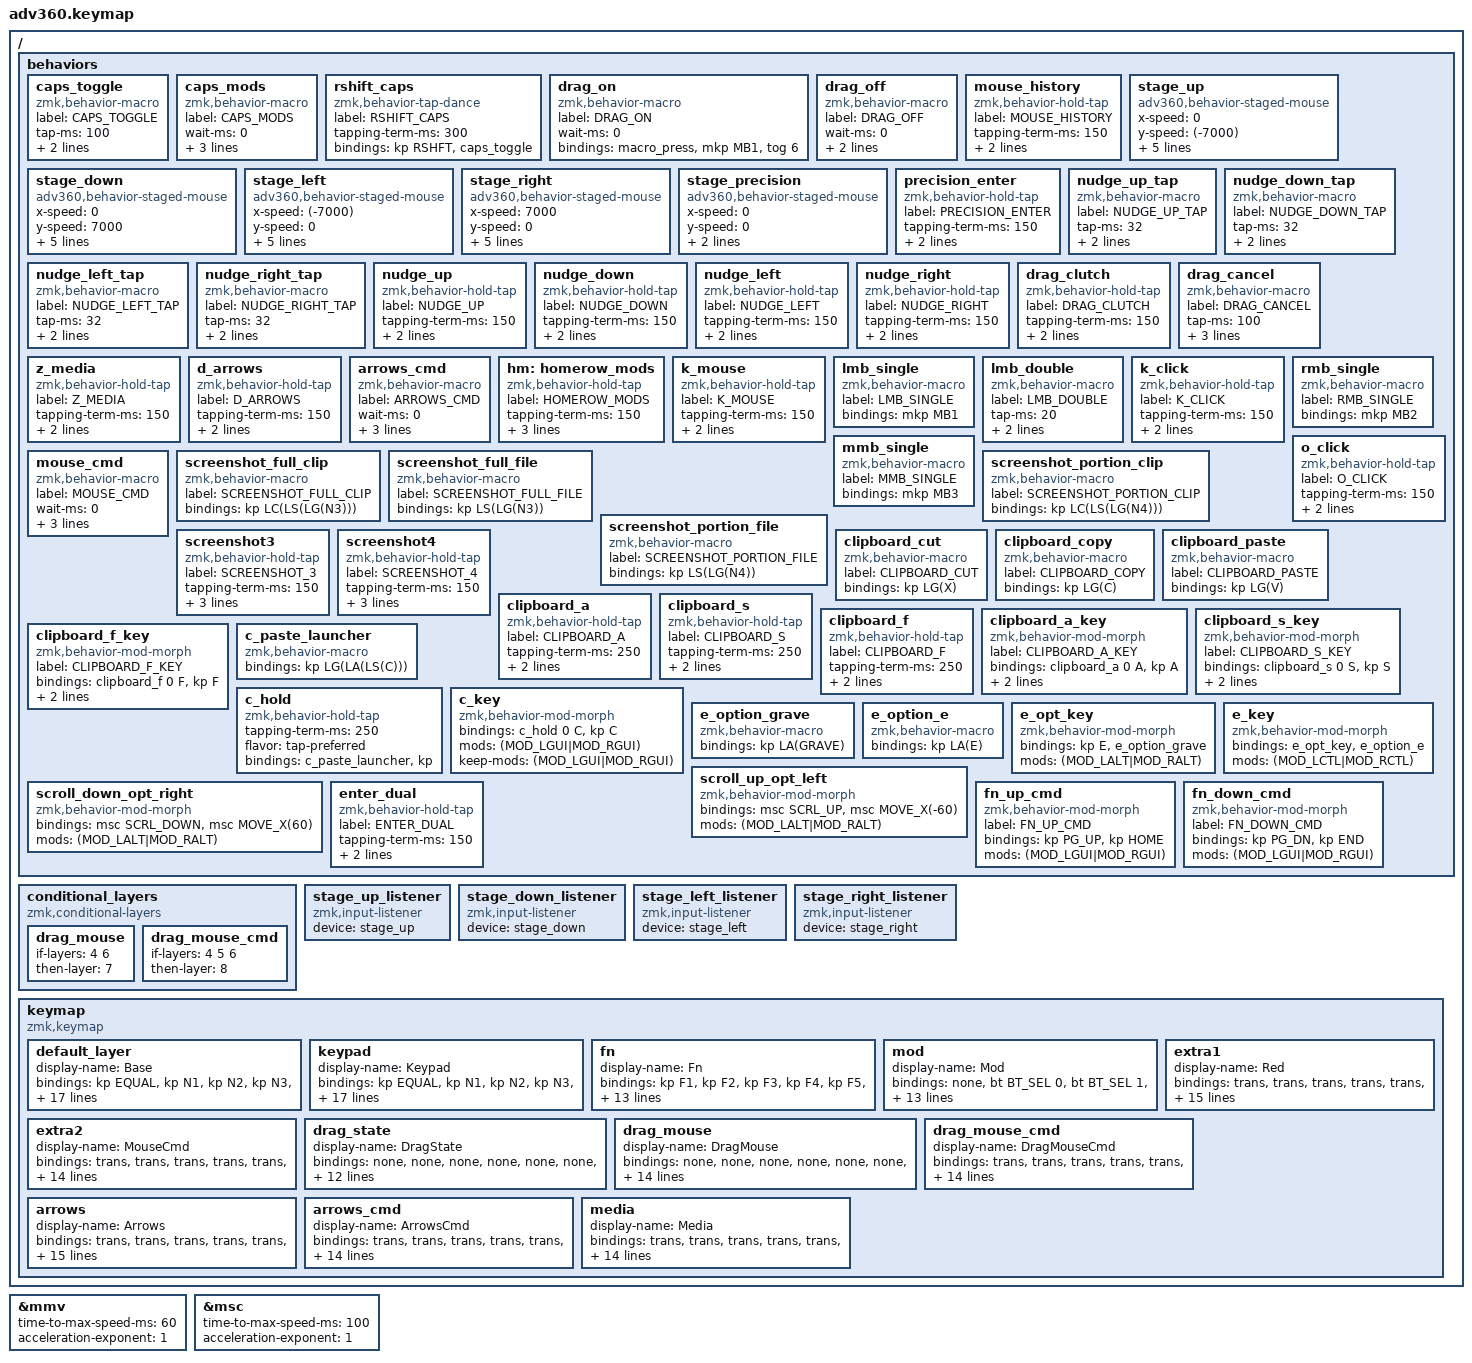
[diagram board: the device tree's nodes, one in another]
/* Rebuild marker: re-trigger the GitHub Actions firmware build; no functional keymap changes. */
#include <behaviors.dtsi>
#include <dt-bindings/zmk/keys.h>
#include <dt-bindings/zmk/modifiers.h>
#include <dt-bindings/zmk/bt.h>
#include <dt-bindings/zmk/rgb.h>
#include <dt-bindings/zmk/stp.h>
#include <dt-bindings/zmk/backlight.h>
#define ZMK_POINTING_DEFAULT_MOVE_VAL 1800
#define ZMK_POINTING_DEFAULT_SCRL_VAL 30
#include <dt-bindings/zmk/pointing.h>

&mmv {
    time-to-max-speed-ms = <60>;
    acceleration-exponent = <1>;
};

&msc {
    time-to-max-speed-ms = <100>;
    acceleration-exponent = <1>;
};

/ {
    behaviors {
      #include "macros.dtsi"
      #include "version.dtsi"

      // Shift double-tap Caps Lock and mouse-layer controls.
      caps_toggle: caps_toggle {
          compatible = "zmk,behavior-macro";
          label = "CAPS_TOGGLE";
          #binding-cells = <0>;
          tap-ms = <100>;
          wait-ms = <0>;
          bindings = <&kp CAPS>;
      };

      // Hold Command, Option, and Shift while the physical Caps key is held.
      caps_mods: caps_mods {
          compatible = "zmk,behavior-macro";
          label = "CAPS_MODS";
          #binding-cells = <0>;
          wait-ms = <0>;
          bindings = <&macro_press &kp LGUI &kp LALT &kp LSHIFT &macro_pause_for_release &macro_release &kp LSHIFT &kp LALT &kp LGUI>;
      };

      rshift_caps: rshift_caps {
          compatible = "zmk,behavior-tap-dance";
          label = "RSHIFT_CAPS";
          #binding-cells = <0>;
          tapping-term-ms = <300>;
          bindings = <&kp RSHFT>, <&caps_toggle>;
      };

      drag_on: drag_on {
          compatible = "zmk,behavior-macro";
          label = "DRAG_ON";
          #binding-cells = <0>;
          wait-ms = <0>;
          bindings = <&macro_press &mkp MB1 &tog 6>;
      };

      drag_off: drag_off {
          compatible = "zmk,behavior-macro";
          label = "DRAG_OFF";
          #binding-cells = <0>;
          wait-ms = <0>;
          bindings = <&macro_release &mkp MB1 &macro_press &tog 6>;
      };

      mouse_history: mouse_history {
          compatible = "zmk,behavior-hold-tap";
          label = "MOUSE_HISTORY";
          #binding-cells = <2>;
          tapping-term-ms = <150>;
          flavor = "tap-preferred";
          bindings = <&kp>, <&kp>;
      };



      // Experimental Rev4: 1 px immediate nudge, continuous smooth ramp from 50 to 7000 px/s over 470 ms; braking disabled.
      stage_up: stage_up {
          compatible = "adv360,behavior-staged-mouse";
          #binding-cells = <0>;
          x-speed = <0>;
          y-speed = <(-7000)>;
          nudge-px = <1>;
          crawl-speed = <50>;
          crawl-ms = <250>;
          ramp-ms = <220>;
          brake-ms = <0>;
      };
      stage_down: stage_down {
          compatible = "adv360,behavior-staged-mouse";
          #binding-cells = <0>;
          x-speed = <0>;
          y-speed = <7000>;
          nudge-px = <1>;
          crawl-speed = <50>;
          crawl-ms = <250>;
          ramp-ms = <220>;
          brake-ms = <0>;
      };
      stage_left: stage_left {
          compatible = "adv360,behavior-staged-mouse";
          #binding-cells = <0>;
          x-speed = <(-7000)>;
          y-speed = <0>;
          nudge-px = <1>;
          crawl-speed = <50>;
          crawl-ms = <250>;
          ramp-ms = <220>;
          brake-ms = <0>;
      };
      stage_right: stage_right {
          compatible = "adv360,behavior-staged-mouse";
          #binding-cells = <0>;
          x-speed = <7000>;
          y-speed = <0>;
          nudge-px = <1>;
          crawl-speed = <50>;
          crawl-ms = <250>;
          ramp-ms = <220>;
          brake-ms = <0>;
      };
      // Enter held while K activates the mouse layer: fixed-speed precision.
      stage_precision: stage_precision {
          compatible = "adv360,behavior-staged-mouse";
          #binding-cells = <0>;
          x-speed = <0>;
          y-speed = <0>;
          nudge-px = <0>;
          brake-ms = <0>;
      };

      precision_enter: precision_enter {
          compatible = "zmk,behavior-hold-tap";
          label = "PRECISION_ENTER";
          #binding-cells = <2>;
          tapping-term-ms = <150>;
          flavor = "balanced";
          bindings = <&stage_precision>, <&kp>;
      };

      // Mouse-layer taps send a fixed short pulse; holds keep continuous movement.
      nudge_up_tap: nudge_up_tap {
          compatible = "zmk,behavior-macro";
          label = "NUDGE_UP_TAP";
          #binding-cells = <0>;
          tap-ms = <32>;
          wait-ms = <0>;
          bindings = <&macro_tap &mmv MOVE(0,-3000)>;
      };

      nudge_down_tap: nudge_down_tap {
          compatible = "zmk,behavior-macro";
          label = "NUDGE_DOWN_TAP";
          #binding-cells = <0>;
          tap-ms = <32>;
          wait-ms = <0>;
          bindings = <&macro_tap &mmv MOVE(0,3000)>;
      };

      nudge_left_tap: nudge_left_tap {
          compatible = "zmk,behavior-macro";
          label = "NUDGE_LEFT_TAP";
          #binding-cells = <0>;
          tap-ms = <32>;
          wait-ms = <0>;
          bindings = <&macro_tap &mmv MOVE(-3000,0)>;
      };

      nudge_right_tap: nudge_right_tap {
          compatible = "zmk,behavior-macro";
          label = "NUDGE_RIGHT_TAP";
          #binding-cells = <0>;
          tap-ms = <32>;
          wait-ms = <0>;
          bindings = <&macro_tap &mmv MOVE(3000,0)>;
      };

      nudge_up: nudge_up {
          compatible = "zmk,behavior-hold-tap";
          label = "NUDGE_UP";
          #binding-cells = <2>;
          tapping-term-ms = <150>;
          flavor = "tap-preferred";
          bindings = <&mmv>, <&nudge_up_tap>;
      };

      nudge_down: nudge_down {
          compatible = "zmk,behavior-hold-tap";
          label = "NUDGE_DOWN";
          #binding-cells = <2>;
          tapping-term-ms = <150>;
          flavor = "tap-preferred";
          bindings = <&mmv>, <&nudge_down_tap>;
      };

      nudge_left: nudge_left {
          compatible = "zmk,behavior-hold-tap";
          label = "NUDGE_LEFT";
          #binding-cells = <2>;
          tapping-term-ms = <150>;
          flavor = "tap-preferred";
          bindings = <&mmv>, <&nudge_left_tap>;
      };

      nudge_right: nudge_right {
          compatible = "zmk,behavior-hold-tap";
          label = "NUDGE_RIGHT";
          #binding-cells = <2>;
          tapping-term-ms = <150>;
          flavor = "tap-preferred";
          bindings = <&mmv>, <&nudge_right_tap>;
      };

      // K can re-enter the mouse layer during drag lock without typing a K.
      drag_clutch: drag_clutch {
          compatible = "zmk,behavior-hold-tap";
          label = "DRAG_CLUTCH";
          #binding-cells = <2>;
          tapping-term-ms = <150>;
          flavor = "balanced";
          bindings = <&mo>, <&none>;
      };


      // Send Escape while MB1 is still held so a drag is cancelled, not dropped.
      drag_cancel: drag_cancel {
          compatible = "zmk,behavior-macro";
          label = "DRAG_CANCEL";
          #binding-cells = <0>;
          tap-ms = <100>;
          wait-ms = <30>;
          bindings = <&macro_tap &kp ESC &macro_release &mkp MB1 &macro_press &tog 6>;
      };


      z_media: z_media {
          compatible = "zmk,behavior-hold-tap";
          label = "Z_MEDIA";
          #binding-cells = <2>;
          tapping-term-ms = <150>;
          flavor = "balanced";
          bindings = <&mo>, <&kp>;
      };

      d_arrows: d_arrows {
          compatible = "zmk,behavior-hold-tap";
          label = "D_ARROWS";
          #binding-cells = <2>;
          tapping-term-ms = <150>;
          flavor = "balanced";
          bindings = <&mo>, <&kp>;
      };

      arrows_cmd: arrows_cmd {
          compatible = "zmk,behavior-macro";
          label = "ARROWS_CMD";
          #binding-cells = <0>;
          wait-ms = <0>;
          bindings = <&macro_press &kp LGUI &mo 10 &macro_pause_for_release &macro_release &mo 10 &kp LGUI>;
      };

      hm: homerow_mods {
          compatible = "zmk,behavior-hold-tap";
          label = "HOMEROW_MODS";
          #binding-cells = <2>;
          tapping-term-ms = <150>;
          quick_tap_ms = <175>;
          flavor = "tap-preferred";
          bindings = <&kp>, <&kp>;
      };

      k_mouse: k_mouse {
          compatible = "zmk,behavior-hold-tap";
          label = "K_MOUSE";
          #binding-cells = <2>;
          tapping-term-ms = <150>;
          flavor = "balanced";
          bindings = <&mo>, <&kp>;
      };

      lmb_single: lmb_single {
          compatible = "zmk,behavior-macro";
          label = "LMB_SINGLE";
          #binding-cells = <0>;
          bindings = <&mkp MB1>;
      };

      lmb_double: lmb_double {
          compatible = "zmk,behavior-macro";
          label = "LMB_DOUBLE";
          #binding-cells = <0>;
          tap-ms = <20>;
          wait-ms = <40>;
          bindings = <&mkp MB1 &mkp MB1>;
      };

      k_click: k_click {
          compatible = "zmk,behavior-hold-tap";
          label = "K_CLICK";
          #binding-cells = <2>;
          tapping-term-ms = <150>;
          flavor = "tap-preferred";
          bindings = <&lmb_double>, <&lmb_single>;
      };

      rmb_single: rmb_single {
          compatible = "zmk,behavior-macro";
          label = "RMB_SINGLE";
          #binding-cells = <0>;
          bindings = <&mkp MB2>;
      };

      mmb_single: mmb_single {
          compatible = "zmk,behavior-macro";
          label = "MMB_SINGLE";
          #binding-cells = <0>;
          bindings = <&mkp MB3>;
      };

      o_click: o_click {
          compatible = "zmk,behavior-hold-tap";
          label = "O_CLICK";
          #binding-cells = <2>;
          tapping-term-ms = <150>;
          flavor = "tap-preferred";
          bindings = <&mmb_single>, <&rmb_single>;
      };

      mouse_cmd: mouse_cmd {
          compatible = "zmk,behavior-macro";
          label = "MOUSE_CMD";
          #binding-cells = <0>;
          wait-ms = <0>;
          bindings = <&macro_press &kp LGUI &mo 5 &macro_pause_for_release &macro_release &mo 5 &kp LGUI>;
      };

      screenshot_full_clip: screenshot_full_clip {
          compatible = "zmk,behavior-macro";
          label = "SCREENSHOT_FULL_CLIP";
          #binding-cells = <0>;
          bindings = <&kp LC(LS(LG(N3)))>;
      };

      screenshot_full_file: screenshot_full_file {
          compatible = "zmk,behavior-macro";
          label = "SCREENSHOT_FULL_FILE";
          #binding-cells = <0>;
          bindings = <&kp LS(LG(N3))>;
      };

      screenshot_portion_clip: screenshot_portion_clip {
          compatible = "zmk,behavior-macro";
          label = "SCREENSHOT_PORTION_CLIP";
          #binding-cells = <0>;
          bindings = <&kp LC(LS(LG(N4)))>;
      };

      screenshot_portion_file: screenshot_portion_file {
          compatible = "zmk,behavior-macro";
          label = "SCREENSHOT_PORTION_FILE";
          #binding-cells = <0>;
          bindings = <&kp LS(LG(N4))>;
      };

      screenshot3: screenshot3 {
          compatible = "zmk,behavior-hold-tap";
          label = "SCREENSHOT_3";
          #binding-cells = <2>;
          tapping-term-ms = <150>;
          flavor = "tap-preferred";
          bindings = <&screenshot_full_file>, <&screenshot_full_clip>;
      };

      screenshot4: screenshot4 {
          compatible = "zmk,behavior-hold-tap";
          label = "SCREENSHOT_4";
          #binding-cells = <2>;
          tapping-term-ms = <150>;
          flavor = "tap-preferred";
          bindings = <&screenshot_portion_file>, <&screenshot_portion_clip>;
      };

      clipboard_cut: clipboard_cut {
          compatible = "zmk,behavior-macro";
          label = "CLIPBOARD_CUT";
          #binding-cells = <0>;
          bindings = <&kp LG(X)>;
      };

      clipboard_copy: clipboard_copy {
          compatible = "zmk,behavior-macro";
          label = "CLIPBOARD_COPY";
          #binding-cells = <0>;
          bindings = <&kp LG(C)>;
      };

      clipboard_paste: clipboard_paste {
          compatible = "zmk,behavior-macro";
          label = "CLIPBOARD_PASTE";
          #binding-cells = <0>;
          bindings = <&kp LG(V)>;
      };

      clipboard_a: clipboard_a {
          compatible = "zmk,behavior-hold-tap";
          label = "CLIPBOARD_A";
          #binding-cells = <2>;
          tapping-term-ms = <250>;
          flavor = "tap-preferred";
          bindings = <&clipboard_cut>, <&kp>;
      };

      clipboard_s: clipboard_s {
          compatible = "zmk,behavior-hold-tap";
          label = "CLIPBOARD_S";
          #binding-cells = <2>;
          tapping-term-ms = <250>;
          flavor = "tap-preferred";
          bindings = <&clipboard_copy>, <&kp>;
      };

      clipboard_f: clipboard_f {
          compatible = "zmk,behavior-hold-tap";
          label = "CLIPBOARD_F";
          #binding-cells = <2>;
          tapping-term-ms = <250>;
          flavor = "tap-preferred";
          bindings = <&clipboard_paste>, <&kp>;
      };

      clipboard_a_key: clipboard_a_key {
          compatible = "zmk,behavior-mod-morph";
          label = "CLIPBOARD_A_KEY";
          #binding-cells = <0>;
          bindings = <&clipboard_a 0 A>, <&kp A>;
          mods = <(MOD_LGUI|MOD_RGUI)>;
          keep-mods = <(MOD_LGUI|MOD_RGUI)>;
      };

      clipboard_s_key: clipboard_s_key {
          compatible = "zmk,behavior-mod-morph";
          label = "CLIPBOARD_S_KEY";
          #binding-cells = <0>;
          bindings = <&clipboard_s 0 S>, <&kp S>;
          mods = <(MOD_LGUI|MOD_RGUI)>;
          keep-mods = <(MOD_LGUI|MOD_RGUI)>;
      };

      clipboard_f_key: clipboard_f_key {
          compatible = "zmk,behavior-mod-morph";
          label = "CLIPBOARD_F_KEY";
          #binding-cells = <0>;
          bindings = <&clipboard_f 0 F>, <&kp F>;
          mods = <(MOD_LGUI|MOD_RGUI)>;
          keep-mods = <(MOD_LGUI|MOD_RGUI)>;
      };

      c_paste_launcher: c_paste_launcher {
          compatible = "zmk,behavior-macro";
          #binding-cells = <0>;
          bindings = <&kp LG(LA(LS(C)))>;
      };

      c_hold: c_hold {
          compatible = "zmk,behavior-hold-tap";
          #binding-cells = <2>;
          tapping-term-ms = <250>;
          flavor = "tap-preferred";
          bindings = <&c_paste_launcher>, <&kp>;
      };

      c_key: c_key {
          compatible = "zmk,behavior-mod-morph";
          #binding-cells = <0>;
          bindings = <&c_hold 0 C>, <&kp C>;
          mods = <(MOD_LGUI|MOD_RGUI)>;
          keep-mods = <(MOD_LGUI|MOD_RGUI)>;
      };

      // Ctrl+E becomes Option+E; Option+E becomes Option+Backtick.
      // Modifier-morph consumes the triggering modifier rather than forwarding it.
      e_option_grave: e_option_grave {
          compatible = "zmk,behavior-macro";
          #binding-cells = <0>;
          bindings = <&kp LA(GRAVE)>;
      };
      e_option_e: e_option_e {
          compatible = "zmk,behavior-macro";
          #binding-cells = <0>;
          bindings = <&kp LA(E)>;
      };
      e_opt_key: e_opt_key {
          compatible = "zmk,behavior-mod-morph";
          #binding-cells = <0>;
          bindings = <&kp E>, <&e_option_grave>;
          mods = <(MOD_LALT|MOD_RALT)>;
      };
      e_key: e_key {
          compatible = "zmk,behavior-mod-morph";
          #binding-cells = <0>;
          bindings = <&e_opt_key>, <&e_option_e>;
          mods = <(MOD_LCTL|MOD_RCTL)>;
      };

      // Shared by D Arrows and K Mouse (including drag and Cmd companion layers):
      // plain or Cmd + Y/H sends vertical scroll; Option + Y/H sends horizontal scroll.
      // Modifiers also reach macOS, so host apps/BTT may interpret events as zoom.
      // Horizontal speed calibrated at 60 vs vertical 30; both use &msc's
      // shared 100 ms acceleration ramp and exponent 1. Tune after hardware test.
      scroll_up_opt_left: scroll_up_opt_left {
          compatible = "zmk,behavior-mod-morph";
          #binding-cells = <0>;
          bindings = <&msc SCRL_UP>, <&msc MOVE_X(-60)>;
          mods = <(MOD_LALT|MOD_RALT)>;
      };
      scroll_down_opt_right: scroll_down_opt_right {
          compatible = "zmk,behavior-mod-morph";
          #binding-cells = <0>;
          bindings = <&msc SCRL_DOWN>, <&msc MOVE_X(60)>;
          mods = <(MOD_LALT|MOD_RALT)>;
      };

      // Physical Enter: hold for Shift+Enter, tap for Enter.
      enter_dual: enter_dual {
          compatible = "zmk,behavior-hold-tap";
          label = "ENTER_DUAL";
          #binding-cells = <2>;
          tapping-term-ms = <150>;
          flavor = "hold-preferred";
          bindings = <&kp>, <&kp>;
      };

      fn_up_cmd: fn_up_cmd {
          compatible = "zmk,behavior-mod-morph";
          label = "FN_UP_CMD";
          #binding-cells = <0>;
          bindings = <&kp PG_UP>, <&kp HOME>;
          mods = <(MOD_LGUI|MOD_RGUI)>;
      };

      fn_down_cmd: fn_down_cmd {
          compatible = "zmk,behavior-mod-morph";
          label = "FN_DOWN_CMD";
          #binding-cells = <0>;
          bindings = <&kp PG_DN>, <&kp END>;
          mods = <(MOD_LGUI|MOD_RGUI)>;
      };



    };

  // Only expose drag-off on U while the mouse clutch is held.
  conditional_layers {
    compatible = "zmk,conditional-layers";
    drag_mouse {
      if-layers = <4 6>;
      then-layer = <7>;
    };
    drag_mouse_cmd {
      if-layers = <4 5 6>;
      then-layer = <8>;
    };
  };

  // Route generated staged movement through ZMK's pointer input pipeline.
  stage_up_listener: stage_up_listener {
      compatible = "zmk,input-listener";
      device = <&stage_up>;
  };
  stage_down_listener: stage_down_listener {
      compatible = "zmk,input-listener";
      device = <&stage_down>;
  };
  stage_left_listener: stage_left_listener {
      compatible = "zmk,input-listener";
      device = <&stage_left>;
  };
  stage_right_listener: stage_right_listener {
      compatible = "zmk,input-listener";
      device = <&stage_right>;
  };

  keymap {
    compatible = "zmk,keymap";

    default_layer {
      display-name = "Base";
      bindings = <
        &kp EQUAL &kp N1 &kp N2 &kp N3 &kp N4 &kp N5 &mo 1 &mo 3 &kp N6 &kp N7 &kp N8 &kp N9 &kp N0 &kp MINUS &kp TAB &kp Q &kp W &e_key &kp R &kp T &none &screenshot3 0 0 &kp Y &kp U &kp I &kp O &kp P &kp BSLH &kp ESC &clipboard_a_key &clipboard_s_key &d_arrows 9 D &clipboard_f_key &kp G &none &kp HOME &kp END &kp LGUI &mo 11 &screenshot4 0 0 &kp H &kp J &k_mouse 4 K &kp L &kp SEMI &kp SQT &kp LSHFT &kp Z &kp X &c_key &kp V &kp B &kp LCTRL &kp PG_UP &kp N &kp M &kp COMMA &kp DOT &kp FSLH &rshift_caps &mo 2 &kp GRAVE &caps_mods &kp LEFT &kp RIGHT &kp SPACE &kp LGUI &kp LALT &kp PG_DN &kp BSPC &enter_dual LS(ENTER) ENTER &kp UP &kp DOWN &kp LBKT &kp RBKT &mo 2
      >;
    };
    keypad {
      display-name = "Keypad";
      bindings = <
        &kp EQUAL &kp N1    &kp N2   &kp N3   &kp N4     &kp N5 &trans                                                           &mo 3 &kp N6 &kp KP_NUM &kp KP_EQUAL &kp KP_DIVIDE &kp KP_MULTIPLY &kp MINUS
        &kp TAB   &kp Q     &kp W    &e_key    &kp R      &kp T  &none                                                            &screenshot3 0 0&kp Y  &kp KP_N7  &kp KP_N8    &kp KP_N9     &kp KP_MINUS    &kp BSLH
        &kp ESC   &clipboard_a_key &clipboard_s_key &kp D &clipboard_f_key &kp G  &none           &kp LCTRL &kp LALT &kp LGUI  &kp RCTRL           &screenshot4 0 0&kp H  &kp KP_N4  &kp KP_N5    &kp KP_N6     &kp KP_PLUS     &kp SQT
        &kp LSHFT &kp Z     &kp X    &c_key    &kp V      &kp B                            &kp HOME &kp PG_UP                           &kp N  &kp KP_N1  &kp KP_N2    &kp KP_N3     &kp KP_ENTER    &rshift_caps
        &mo 2     &kp GRAVE &caps_mods &kp LEFT &kp RIGHT                &kp BSPC &kp DEL   &kp END  &kp PG_DN &enter_dual LS(ENTER) ENTER &kp KP_N0              &kp UP     &kp DOWN     &kp KP_DOT    &kp RBKT        &mo 2
      >;
    };
    fn {
      display-name = "Fn";
      bindings = <
        &kp F1 &kp F2 &kp F3 &kp F4 &kp F5 &kp F6 &mo 1                                           &mo 3 &kp F7 &kp F8 &kp F9 &kp F10 &kp F11 &kp F12
        &trans &trans &trans &trans &trans &trans  &none                                           &screenshot3 0 0&trans &trans &trans &trans  &trans  &trans
        &trans &trans &trans &trans &trans &trans  &none        &trans &trans &trans &trans        &screenshot4 0 0&trans &trans &trans &trans  &trans  &trans
        &trans &trans &trans &trans &trans &trans                      &trans &trans                     &trans &trans &trans &trans  &trans &trans
        &trans &trans &trans &trans &trans               &trans &trans &trans &trans &kp DEL &trans              &fn_up_cmd &fn_down_cmd &trans  &trans  &trans
      >;
    };
    mod {
      display-name = "Mod";
      bindings = <
        &none &bt BT_SEL 0 &bt BT_SEL 1 &bt BT_SEL 2 &bt BT_SEL 3 &bt BT_SEL 4 &none                                                                     &trans                 &none        &none        &none        &none &none &none
        &none &none        &none        &none        &none        &none        &bootloader                                                               &bootloader            &none        &none        &none        &none &none &none
        &studio_unlock &none        &none        &none        &none        &none        &none                   &none &none &bt BT_CLR &none                      &stp STP_BAT &none        &none        &none        &none &none &none
        &none &none        &none        &none        &macro_ver   &none                                      &none &none                                                        &none        &none        &none        &none &none &none
        &none &none        &none        &none        &none                                       &none &none &none &none      &bl BL_TOG &rgb_ug RGB_TOG                                     &bl BL_INC   &bl BL_DEC   &none &none &none
      >;
    };
    extra1 {
      display-name = "Red";
      bindings = <
        &trans &trans &trans &trans &trans &trans &trans                                      &mo 3  &trans &trans &trans &trans &trans &trans
        &trans &trans &trans &stage_up &trans &trans &none                                      &screenshot3 0 0&scroll_up_opt_left &drag_on &none &kp O &trans &trans
        &trans &kp A &stage_left &stage_down &stage_right &trans &none           &trans &trans &mouse_cmd &trans               &screenshot4 0 0&scroll_down_opt_right &mkp MB1 &trans &o_click 0 0 &trans &trans
        &trans &trans &trans &trans &trans &trans                                             &trans &trans                    &trans &trans &kp UP &kp RIGHT &trans &trans
        &trans &trans &trans &trans &trans                                      &trans &mouse_cmd &trans &trans &trans &precision_enter 0 ENTER              &kp LEFT &kp DOWN &trans &trans &trans
      >;
    };

    extra2 {
      display-name = "MouseCmd";
      bindings = <
        &trans &trans &trans &trans &trans &trans &trans                                      &trans &trans &trans &trans &trans &trans &trans
        &trans &trans &trans &trans &trans &trans &none                                      &screenshot3 0 0&scroll_up_opt_left &trans &trans &trans &trans &trans
        &trans &trans &trans &trans &trans &trans &none           &trans &trans &trans &trans               &screenshot4 0 0&scroll_down_opt_right &trans &trans &trans &trans &trans &trans
        &trans &trans &trans &trans &trans &trans                                             &trans &trans                    &trans &trans &trans &trans &trans &trans
        &trans &trans &trans &trans &trans                                      &trans &trans &trans &trans &trans &trans              &trans &trans &trans &trans &trans
      >;
    };
    drag_state {
      display-name = "DragState";
      bindings = <
        &none &none &none &none &none &none &none &none &none &none &none &none &none &none &kp TAB &none &none &none &none &none &none &screenshot3 0 0&none &none &none &none &none &none &drag_cancel &none &none &none &none &none &none &none &none &kp LGUI &none &screenshot4 0 0&none &none &drag_clutch 4 0 &none &none &none &kp LSHFT &none &none &none &none &none &kp LCTRL &none &none &none &none &none &none &kp RSHFT &none &none &none &none &none &none &kp LGUI &kp LALT &none &none &none &none &none &none &none &none
      >;
    };
    drag_mouse {
      display-name = "DragMouse";
      bindings = <
        &none &none &none &none &none &none &none &mo 3 &none &none &none &none &none &none &kp TAB &none &none &stage_up &none &none &none &screenshot3 0 0&scroll_up_opt_left &drag_off &none &none &none &none &drag_cancel &none &stage_left &stage_down &stage_right &none &none &none &none &trans &none &screenshot4 0 0&scroll_down_opt_right &mkp MB1 &trans &o_click 0 0 &none &none &kp LSHFT &none &none &none &none &none &kp LCTRL &none &none &none &kp UP &kp RIGHT &none &kp RSHFT &none &none &none &none &none &none &trans &kp LALT &none &none &none &kp LEFT &kp DOWN &none &none &none
      >;
    };
    drag_mouse_cmd {
      display-name = "DragMouseCmd";
      bindings = <
        &trans &trans &trans &trans &trans &trans &trans &trans &trans &trans &trans &trans &trans &trans &trans &trans &trans &trans &trans &trans &none &screenshot3 0 0&scroll_up_opt_left &trans &trans &trans &trans &trans &trans &trans &trans &trans &trans &trans &none &trans &trans &trans &trans &screenshot4 0 0&scroll_down_opt_right &trans &trans &trans &trans &trans &trans &trans &trans &trans &trans &trans &trans &trans &trans &trans &trans &trans &trans &trans &trans &trans &trans &trans &trans &trans &trans &trans &trans &trans &trans &trans &trans &trans &trans &trans
      >;
    };
    arrows {
      display-name = "Arrows";
      bindings = <
        &trans &trans &trans &trans &trans &trans &trans &trans &trans &trans &trans &trans &trans &trans &trans &kp A &kp S &trans &kp F &trans &none &screenshot3 0 0&scroll_up_opt_left &trans &kp UP &kp O&trans &trans &trans &trans &trans &trans &trans &trans &none &trans &trans &arrows_cmd &trans &screenshot4 0 0&scroll_down_opt_right &kp LEFT &kp DOWN &kp RIGHT &trans &trans &trans &trans &trans &trans &trans &trans &trans &trans &trans &trans &trans &trans &trans &trans &trans &trans &trans &trans &trans &trans &arrows_cmd &trans &trans &trans &trans &trans &trans &trans &trans &trans
      >;
    };
    arrows_cmd {
      display-name = "ArrowsCmd";
      bindings = <
        &trans &trans &trans &trans &trans &trans &trans &trans &trans &trans &trans &trans &trans &trans &trans &trans &trans &trans &trans &trans &none &screenshot3 0 0&scroll_up_opt_left &trans &trans &trans &trans &trans &trans &trans &trans &trans &trans &trans &none &trans &trans &trans &trans &screenshot4 0 0&scroll_down_opt_right &trans &trans &trans &trans &trans &trans &trans &trans &trans &trans &trans &trans &trans &trans &trans &trans &trans &trans &trans &trans &trans &trans &trans &trans &trans &trans &trans &trans &trans &trans &trans &trans &trans &trans &trans
      >;
    };
    media {
      display-name = "Media";
      bindings = <
        &trans &trans &trans &trans &trans &trans &trans                       &trans &trans &trans &trans &trans &trans &trans
        &trans &trans &trans &trans &trans &trans &trans                       &trans &kp C_BRIGHTNESS_INC &kp C_MUTE &kp C_VOLUME_DOWN &kp C_VOLUME_UP &trans &trans
        &trans &trans &trans &trans &trans &trans &trans &trans &trans &trans &trans &trans &kp C_BRIGHTNESS_DEC &kp C_PREVIOUS &kp C_PLAY_PAUSE &kp C_NEXT &trans &trans
        &trans &trans &trans &trans &trans &trans                  &trans &trans                     &trans &trans &trans &trans &trans &trans
        &trans &trans &trans &trans &trans               &trans &trans &trans &trans &trans &trans              &trans &trans &trans &trans &trans
      >;
    };
  };
};
